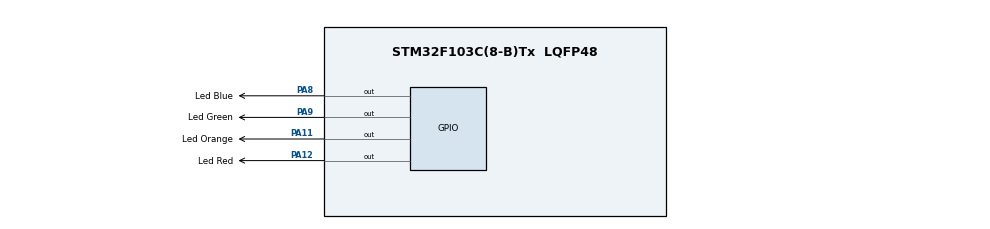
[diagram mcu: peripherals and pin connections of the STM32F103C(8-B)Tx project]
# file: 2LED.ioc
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FREERTOS.Tasks01=defaultTask,24,128,StartDefaultTask,Default,NULL,Dynamic,NULL,NULL;FlashRed,24,128,FlashRedLedTask,Default,NULL,Dynamic,NULL,NULL;FlashGreen,24,128,FlashGreenLedTask,Default,NULL,Dynamic,NULL,NULL
FREERTOS.configUSE_NEWLIB_REENTRANT=1
Mcu.Family=STM32F1
Mcu.Name=STM32F103C(8-B)Tx
Mcu.Package=LQFP48
NVIC.PriorityGroup=NVIC_PRIORITYGROUP_4
NVIC.TIM4_IRQn=true\:15\:0\:false\:false\:true\:false\:false\:true\:true
NVIC.TimeBase=TIM4_IRQn
NVIC.TimeBaseIP=TIM4
PA11.GPIO_Label=Led Orange
PA11.Signal=GPIO_Output
PA12.GPIO_Label=Led Red
PA12.Signal=GPIO_Output
PA13.Mode=Serial_Wire
PA13.Signal=SYS_JTMS-SWDIO
PA14.Mode=Serial_Wire
PA14.Signal=SYS_JTCK-SWCLK
PA8.GPIO_Label=Led Blue
PA8.Signal=GPIO_Output
PA9.GPIO_Label=Led Green
PA9.Signal=GPIO_Output
ProjectManager.HeapSize=0x200
ProjectManager.StackSize=0x400
ProjectManager.TargetToolchain=STM32CubeIDE
RCC.APB1Freq_Value=8000000
RCC.APB2Freq_Value=8000000
VP_FREERTOS_VS_CMSIS_V2.Mode=CMSIS_V2
VP_SYS_VS_tim4.Mode=TIM4
board=custom

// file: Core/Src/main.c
/* USER CODE BEGIN Header */
/**
  ******************************************************************************
  * @file           : main.c
  * @brief          : Main program body
  ******************************************************************************
  * @attention
  *
  * Copyright (c) 2024 STMicroelectronics.
  * All rights reserved.
  *
  * This software is licensed under terms that can be found in the LICENSE file
  * in the root directory of this software component.
  * If no LICENSE file comes with this software, it is provided AS-IS.
  *
  ******************************************************************************
  */
/* USER CODE END Header */
#include "main.h"
#include "cmsis_os.h"

/* Definitions for defaultTask */
osThreadId_t defaultTaskHandle;
const osThreadAttr_t defaultTask_attributes = {
  .name = "defaultTask",
  .stack_size = 128 * 4,
  .priority = (osPriority_t) osPriorityNormal,
};
/* Definitions for FlashRed */
osThreadId_t FlashRedHandle;
const osThreadAttr_t FlashRed_attributes = {
  .name = "FlashRed",
  .stack_size = 128 * 4,
  .priority = (osPriority_t) osPriorityNormal,
};
/* Definitions for FlashGreen */
osThreadId_t FlashGreenHandle;
const osThreadAttr_t FlashGreen_attributes = {
  .name = "FlashGreen",
  .stack_size = 128 * 4,
  .priority = (osPriority_t) osPriorityNormal,
};

void SystemClock_Config(void);
static void MX_GPIO_Init(void);
void StartDefaultTask(void *argument);
void FlashRedLedTask(void *argument);
void FlashGreenLedTask(void *argument);

int main(void)
{

  /* MCU Configuration--------------------------------------------------------*/

  /* Reset of all peripherals, Initializes the Flash interface and the Systick. */
  HAL_Init();

  /* Configure the system clock */
  SystemClock_Config();

  /* Initialize all configured peripherals */
  MX_GPIO_Init();

  /* Init scheduler */
  osKernelInitialize();

  /* Create the thread(s) */
  /* creation of defaultTask */
  defaultTaskHandle = osThreadNew(StartDefaultTask, NULL, &defaultTask_attributes);

  /* creation of FlashRed */
  FlashRedHandle = osThreadNew(FlashRedLedTask, NULL, &FlashRed_attributes);

  /* creation of FlashGreen */
  FlashGreenHandle = osThreadNew(FlashGreenLedTask, NULL, &FlashGreen_attributes);

  /* Start scheduler */
  osKernelStart();

  /* We should never get here as control is now taken by the scheduler */

  /* Infinite loop */
  while (1)
  {

  }
}

void SystemClock_Config(void)
{
  RCC_OscInitTypeDef RCC_OscInitStruct = {0};
  RCC_ClkInitTypeDef RCC_ClkInitStruct = {0};

  /** Initializes the RCC Oscillators according to the specified parameters
  * in the RCC_OscInitTypeDef structure.
  */
  RCC_OscInitStruct.OscillatorType = RCC_OSCILLATORTYPE_HSI;
  RCC_OscInitStruct.HSIState = RCC_HSI_ON;
  RCC_OscInitStruct.HSICalibrationValue = RCC_HSICALIBRATION_DEFAULT;
  RCC_OscInitStruct.PLL.PLLState = RCC_PLL_NONE;
  if (HAL_RCC_OscConfig(&RCC_OscInitStruct) != HAL_OK)
  {
    Error_Handler();
  }

  /** Initializes the CPU, AHB and APB buses clocks
  */
  RCC_ClkInitStruct.ClockType = RCC_CLOCKTYPE_HCLK|RCC_CLOCKTYPE_SYSCLK
                              |RCC_CLOCKTYPE_PCLK1|RCC_CLOCKTYPE_PCLK2;
  RCC_ClkInitStruct.SYSCLKSource = RCC_SYSCLKSOURCE_HSI;
  RCC_ClkInitStruct.AHBCLKDivider = RCC_SYSCLK_DIV1;
  RCC_ClkInitStruct.APB1CLKDivider = RCC_HCLK_DIV1;
  RCC_ClkInitStruct.APB2CLKDivider = RCC_HCLK_DIV1;

  if (HAL_RCC_ClockConfig(&RCC_ClkInitStruct, FLASH_LATENCY_0) != HAL_OK)
  {
    Error_Handler();
  }
}

static void MX_GPIO_Init(void)
{
  GPIO_InitTypeDef GPIO_InitStruct = {0};

  /* GPIO Ports Clock Enable */
  __HAL_RCC_GPIOA_CLK_ENABLE();

  /*Configure GPIO pin Output Level */
  HAL_GPIO_WritePin(GPIOA, Led_Blue_Pin|Led_Green_Pin|Led_Orange_Pin|Led_Red_Pin, GPIO_PIN_RESET);

  /*Configure GPIO pins : Led_Blue_Pin Led_Green_Pin Led_Orange_Pin Led_Red_Pin */
  GPIO_InitStruct.Pin = Led_Blue_Pin|Led_Green_Pin|Led_Orange_Pin|Led_Red_Pin;
  GPIO_InitStruct.Mode = GPIO_MODE_OUTPUT_PP;
  GPIO_InitStruct.Pull = GPIO_NOPULL;
  GPIO_InitStruct.Speed = GPIO_SPEED_FREQ_LOW;
  HAL_GPIO_Init(GPIOA, &GPIO_InitStruct);

}

void StartDefaultTask(void *argument)
{
  for(;;)
  {
    osDelay(1);
  }
}

void FlashRedLedTask(void *argument)
{
  /* USER CODE BEGIN FlashRedLedTask */
  /* Infinite loop */
	for(;;)
	{
		HAL_GPIO_WritePin(Led_Orange_GPIO_Port , Led_Orange_Pin , GPIO_PIN_SET);
	    for (int i = 0; i < 10; ++i)
	    { // Toggle Red LED for 0.5 seconds (20 Hz)
	       HAL_GPIO_TogglePin(Led_Red_GPIO_Port, Led_Red_Pin);
	            osDelay(50); // 50ms delay for 20 Hz toggle rate
	        }
	        HAL_GPIO_WritePin(Led_Red_GPIO_Port, Led_Red_Pin, GPIO_PIN_RESET);
	        HAL_GPIO_WritePin(Led_Orange_GPIO_Port, Led_Orange_Pin, GPIO_PIN_RESET);
	        osDelay(1500); // Suspend for 1.5 seconds
	}
  /* USER CODE END FlashRedLedTask */
}

void FlashGreenLedTask(void *argument)
{
  /* USER CODE BEGIN FlashGreenLedTask */
  /* Infinite loop */
	for(;;) {
	        HAL_GPIO_WritePin(Led_Blue_GPIO_Port, Led_Blue_Pin, GPIO_PIN_SET); // Turn Blue LED on
	        for (int i = 0; i < 80; ++i) { // Toggle Green LED for 4 seconds (20 Hz)
	            HAL_GPIO_TogglePin(Led_Green_GPIO_Port, Led_Green_Pin);
	            osDelay(50); // 50ms delay for 20 Hz toggle rate
	        }
	        HAL_GPIO_WritePin(Led_Green_GPIO_Port, Led_Green_Pin, GPIO_PIN_RESET);
	        HAL_GPIO_WritePin(Led_Blue_GPIO_Port, Led_Blue_Pin, GPIO_PIN_RESET);
	        osDelay(6000); // Suspend for 6 seconds
	}
  /* USER CODE END FlashGreenLedTask */
}

void HAL_TIM_PeriodElapsedCallback(TIM_HandleTypeDef *htim)
{
  if (htim->Instance == TIM4) {
    HAL_IncTick();
  }
}

void Error_Handler(void)
{
  __disable_irq();
  while (1)
  {
  }
}
